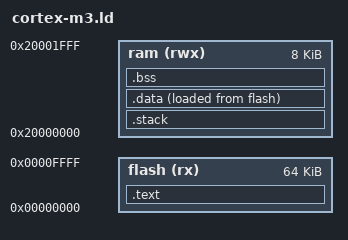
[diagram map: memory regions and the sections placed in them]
/* скрипт линкера для Cortex-M3 */
 
ENTRY(_vector) /* точка входа */

/* конфигурация памяти целевой системы, сильно зависит от микроконтроллера */

MEMORY /* Luminary Micro lm3s811 */ 
{
	flash (rx) : ORIGIN = 0x00000000, LENGTH = 0x00010000
	ram  (rwx) : ORIGIN = 0x20000000, LENGTH = 0x00002000
}
_stack_size = 1K; /* размер стека */

/* описание упаковки секций объектных файлов 
   в целевой файл и размещение в памяти */

SECTIONS
{
	/* секция кода, обеспечиваем нужный порядок сегментов */
	.text : {
		_text = .;
		startup.o(.text) /* в начало кладем таблицу векторов */
		*(.text)         /* а потом все остальное */
	} >flash
	/* стек по рекомендации MISRA располагаем НИЖЕ данных т.к. растет вниз
       (предотвращение затирания данных при переполнении стека) */
	.stack : {
		. = ALIGN(8);
		_stack = .;
		. = . + _stack_size; /* резервируем память под стек */
		_stack_top = .;      /* создаем указатель на вершину стека */
	} >ram
	/* секция инициализированных данных (константы) */
	.data : {
		_data = .;
		*(.data) 
	} >ram AT>flash
	/* секция пустых данных и кучи
	   (переменные и массивы без заданных значений, динамическая память) */
	.bss : { 
		_bss = .;
		*(.bss) 
	} >ram
}
